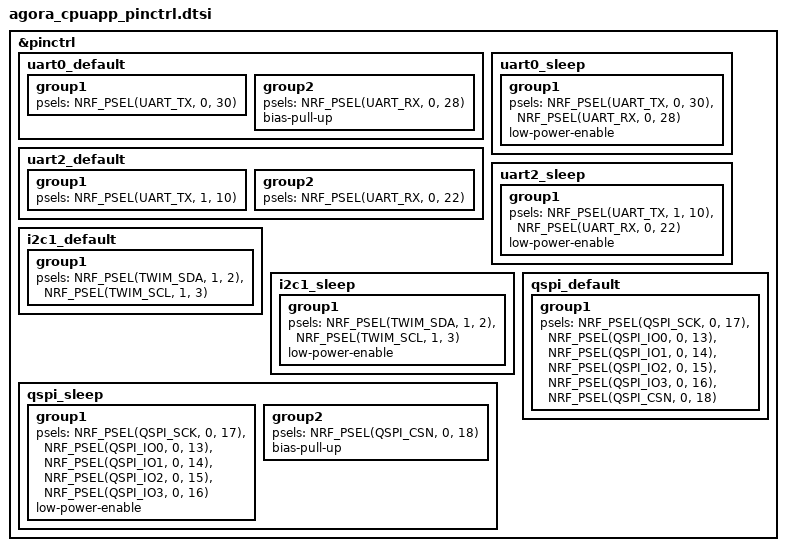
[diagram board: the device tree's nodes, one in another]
&pinctrl {
	uart0_default: uart0_default {
		group1 {
			psels = <NRF_PSEL(UART_TX, 0, 30)>;
		};
		group2 {
			psels = <NRF_PSEL(UART_RX, 0, 28)>;
			bias-pull-up;
		};
	};

	uart0_sleep: uart0_sleep {
		group1 {
			psels = <NRF_PSEL(UART_TX, 0, 30)>,
				<NRF_PSEL(UART_RX, 0, 28)>;
			low-power-enable;
		};
	};

	uart2_default: uart2_default {
		group1 {
			psels = <NRF_PSEL(UART_TX, 1, 10)>;
		};
		group2 {
			psels = <NRF_PSEL(UART_RX, 0, 22)>;
		};
	};

	uart2_sleep: uart2_sleep {
		group1 {
			psels = <NRF_PSEL(UART_TX, 1, 10)>,
				<NRF_PSEL(UART_RX, 0, 22)>;
			low-power-enable;
		};
	};

	i2c1_default: i2c1_default {
		group1 {
			psels = <NRF_PSEL(TWIM_SDA, 1, 2)>,
				<NRF_PSEL(TWIM_SCL, 1, 3)>;
		};
	};

	i2c1_sleep: i2c1_sleep {
		group1 {
			psels = <NRF_PSEL(TWIM_SDA, 1, 2)>,
				<NRF_PSEL(TWIM_SCL, 1, 3)>;
			low-power-enable;
		};
	};

	qspi_default: qspi_default {
		group1 {
			psels = <NRF_PSEL(QSPI_SCK, 0, 17)>,
				<NRF_PSEL(QSPI_IO0, 0, 13)>,
				<NRF_PSEL(QSPI_IO1, 0, 14)>,
				<NRF_PSEL(QSPI_IO2, 0, 15)>,
				<NRF_PSEL(QSPI_IO3, 0, 16)>,
				<NRF_PSEL(QSPI_CSN, 0, 18)>;
			//nordic,drive-mode = <NRF_DRIVE_H0H1>;
		};
	};

	qspi_sleep: qspi_sleep {
		group1 {
			psels = <NRF_PSEL(QSPI_SCK, 0, 17)>,
				<NRF_PSEL(QSPI_IO0, 0, 13)>,
				<NRF_PSEL(QSPI_IO1, 0, 14)>,
				<NRF_PSEL(QSPI_IO2, 0, 15)>,
				<NRF_PSEL(QSPI_IO3, 0, 16)>;
			low-power-enable;
		};
		group2 {
			psels = <NRF_PSEL(QSPI_CSN, 0, 18)>;
			bias-pull-up;
		};
	};
};
